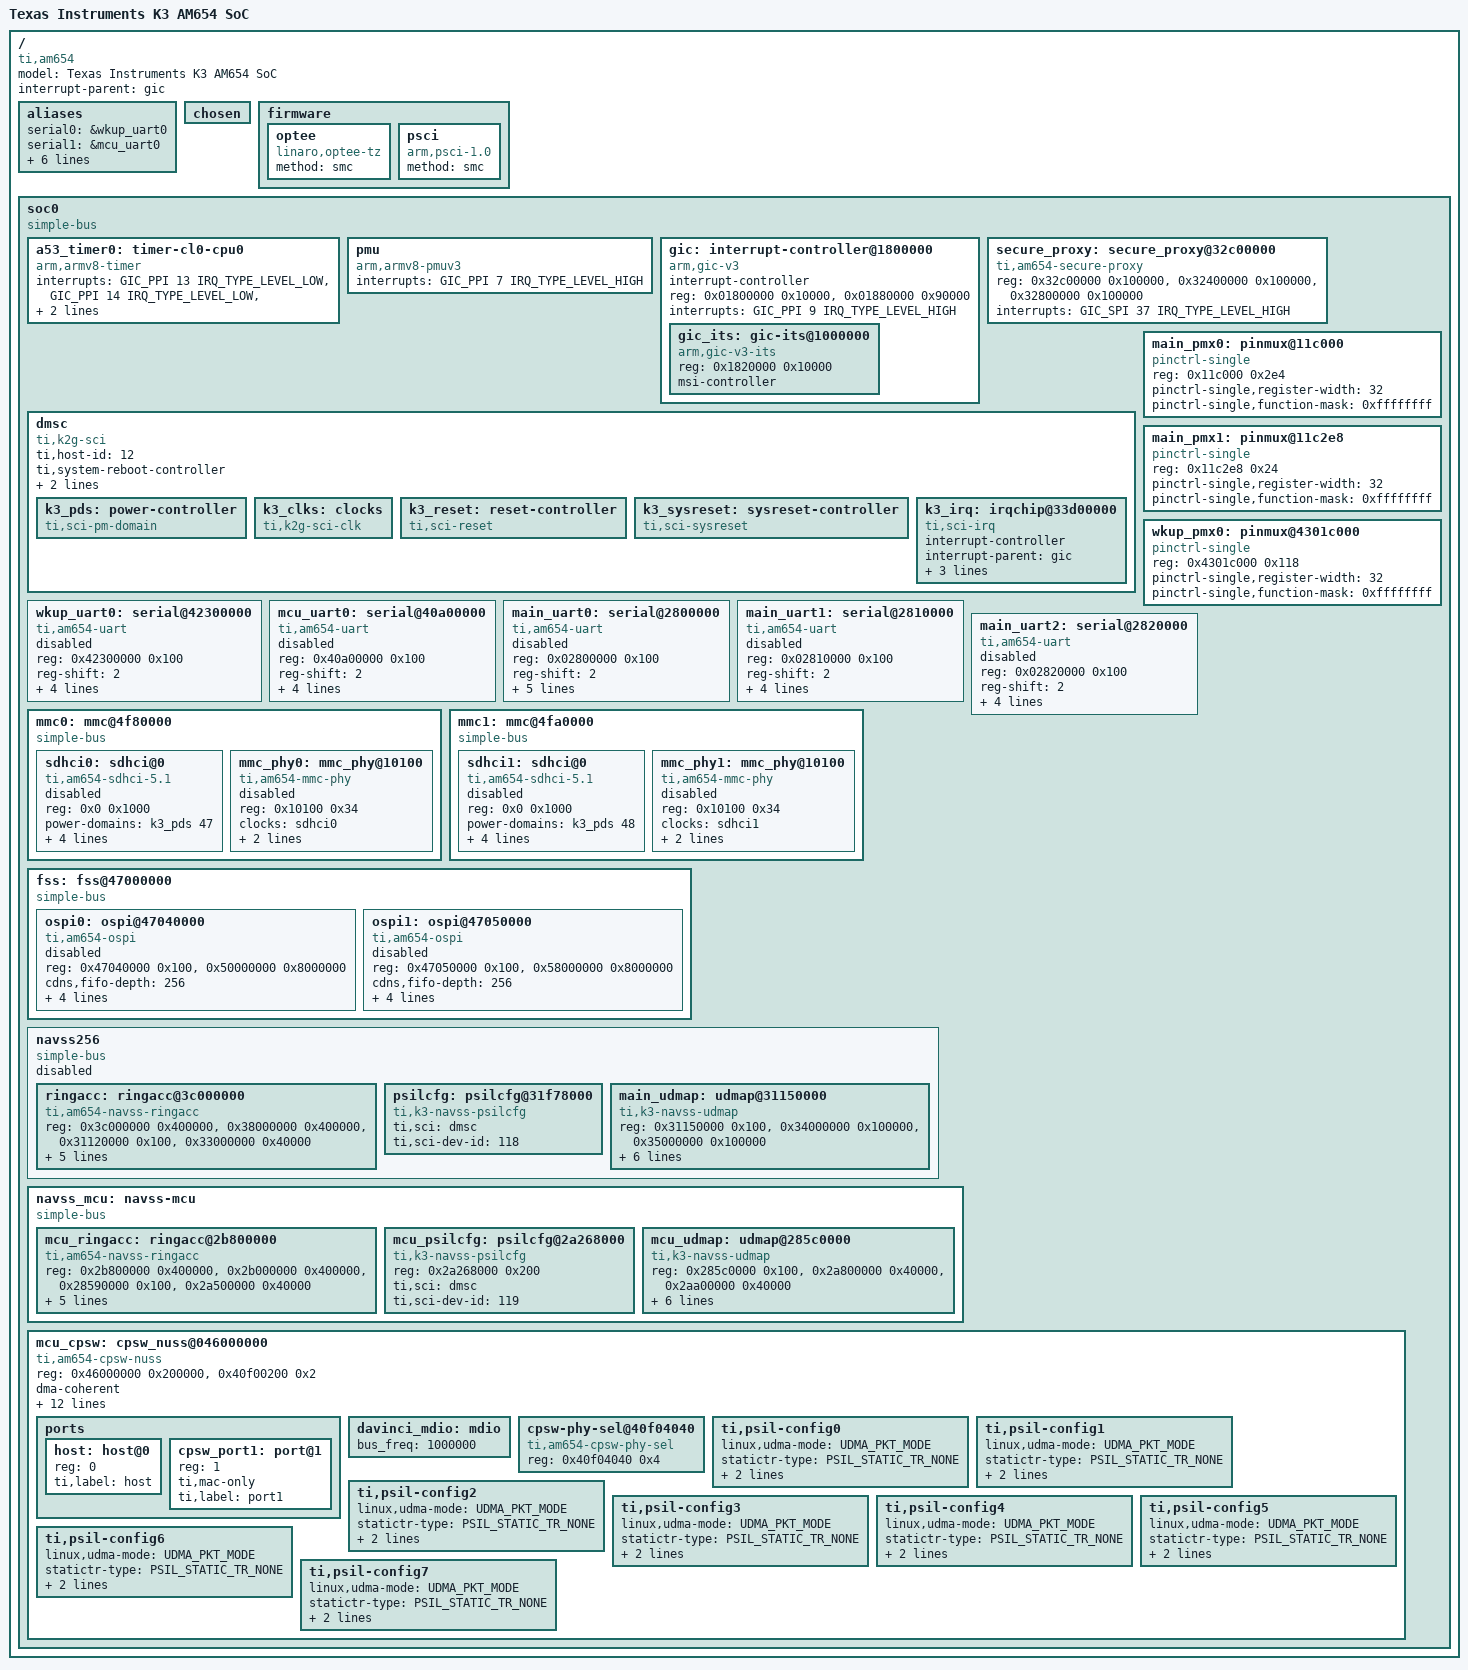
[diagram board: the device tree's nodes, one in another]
// SPDX-License-Identifier: GPL-2.0
/*
 * Device Tree Source for AM6 SoC Family
 *
 * Copyright (C) 2016-2018 Texas Instruments Incorporated - http://www.ti.com/
 */

#include <dt-bindings/gpio/gpio.h>
#include <dt-bindings/interrupt-controller/irq.h>
#include <dt-bindings/interrupt-controller/arm-gic.h>
#include <dt-bindings/pinctrl/k3-am6.h>
#include <dt-bindings/dma/k3-udma.h>

/ {
	model = "Texas Instruments K3 AM654 SoC";
	compatible = "ti,am654";
	interrupt-parent = <&gic>;
	#address-cells = <1>;
	#size-cells = <1>;

	aliases {
		serial0 = &wkup_uart0;
		serial1 = &mcu_uart0;
		serial2 = &main_uart0;
		serial3 = &main_uart1;
		serial4 = &main_uart2;
		spi0 = &ospi0;
		spi1 = &ospi1;
		ethernet0 = &cpsw_port1;
	};

	chosen { };

	firmware {
		optee {
			compatible = "linaro,optee-tz";
			method = "smc";
		};

		psci: psci {
			compatible = "arm,psci-1.0";
			method = "smc";
		};
	};

	soc0: soc0 {
		compatible = "simple-bus";
		#address-cells = <1>;
		#size-cells = <1>;
		ranges;

		a53_timer0: timer-cl0-cpu0 {
			compatible = "arm,armv8-timer";
			interrupts = <GIC_PPI 13 IRQ_TYPE_LEVEL_LOW>, /* cntpsirq */
				     <GIC_PPI 14 IRQ_TYPE_LEVEL_LOW>, /* cntpnsirq */
				     <GIC_PPI 11 IRQ_TYPE_LEVEL_LOW>, /* cntvirq */
				     <GIC_PPI 10 IRQ_TYPE_LEVEL_LOW>; /* cnthpirq */
		};

		pmu: pmu {
			compatible = "arm,armv8-pmuv3";
			/* Recommendation from GIC500 TRM Table A.3 */
			interrupts = <GIC_PPI 7 IRQ_TYPE_LEVEL_HIGH>;
		};

		gic: interrupt-controller@1800000 {
			compatible = "arm,gic-v3";
			#address-cells = <1>;
			#size-cells = <1>;
			ranges;
			#interrupt-cells = <3>;
			interrupt-controller;
			/*
			 * NOTE: we are NOT gicv2 backward compat, so no GICC,
			 * GICH or GICV
			 */
			reg = <0x01800000 0x10000>,	/* GICD */
			      <0x01880000 0x90000>;	/* GICR */

			/*
			 * vcpumntirq:
			 * virtual CPU interface maintenance interrupt
			 */
			interrupts = <GIC_PPI 9 IRQ_TYPE_LEVEL_HIGH>;

			gic_its: gic-its@1000000 {
				compatible = "arm,gic-v3-its";
				reg = <0x1820000 0x10000>;
				msi-controller;
				#msi-cells = <1>;
			};
		};

		secure_proxy: secure_proxy@32c00000 {
			compatible = "ti,am654-secure-proxy";
			#mbox-cells = <1>;
			reg-names = "target_data", "rt", "scfg";
			reg = <0x32c00000 0x100000>,
			      <0x32400000 0x100000>,
			      <0x32800000 0x100000>;
			interrupt-names = "rx_011";
			interrupts = <GIC_SPI 37 IRQ_TYPE_LEVEL_HIGH>;
		};

		dmsc: dmsc {
			compatible = "ti,k2g-sci";
			ti,host-id = <12>;
			#address-cells = <1>;
			#size-cells = <1>;
			ranges;
			/*
			 * In case of rare platforms that does not use am6 as
			 * system master, use /delete-property/
			 */
			ti,system-reboot-controller;
			mbox-names = "rx", "tx";

			mboxes= <&secure_proxy 11>,
				<&secure_proxy 13>;

			k3_pds: power-controller {
				compatible = "ti,sci-pm-domain";
				#power-domain-cells = <1>;
			};

			k3_clks: clocks {
				compatible = "ti,k2g-sci-clk";
				#clock-cells = <2>;
			};

			k3_reset: reset-controller {
				compatible = "ti,sci-reset";
				#reset-cells = <2>;
			};

			k3_sysreset: sysreset-controller {
				compatible = "ti,sci-sysreset";
			};

			k3_irq: irqchip@33d00000 {
				compatible = "ti,sci-irq";
				interrupt-controller;
				interrupt-parent = <&gic>;
				#interrupt-cells = <3>;
				reg = <0x33d00000 0x100000>,
				      <0x33c00000 0x40000>,
				      <0x33c40000 0x40000>,
				      <0x2a700000 0x100000>;
				ia-ids = <179>, <180>, <181>, <189>;
			};
		};

		main_pmx0: pinmux@11c000 {
			compatible = "pinctrl-single";
			reg = <0x11c000 0x2e4>;
			#pinctrl-cells = <1>;
			pinctrl-single,register-width = <32>;
			pinctrl-single,function-mask = <0xffffffff>;
		};

		main_pmx1: pinmux@11c2e8 {
			compatible = "pinctrl-single";
			reg = <0x11c2e8 0x24>;
			#pinctrl-cells = <1>;
			pinctrl-single,register-width = <32>;
			pinctrl-single,function-mask = <0xffffffff>;
		};

		wkup_pmx0: pinmux@4301c000 {
			compatible = "pinctrl-single";
			reg = <0x4301c000 0x118>;
			#pinctrl-cells = <1>;
			pinctrl-single,register-width = <32>;
			pinctrl-single,function-mask = <0xffffffff>;
		};

		wkup_uart0: serial@42300000 {
			compatible = "ti,am654-uart", "ti,omap4-uart", "ns16550a";
			reg = <0x42300000 0x100>;
			reg-shift = <2>;
			reg-io-width = <4>;
			interrupts = <GIC_SPI 697 IRQ_TYPE_LEVEL_HIGH>;
			clock-frequency = <48000000>;
			current-speed = <115200>;
			status = "disabled";
		};

		mcu_uart0: serial@40a00000 {
			compatible = "ti,am654-uart", "ti,omap4-uart", "ns16550a";
			reg = <0x40a00000 0x100>;
			reg-shift = <2>;
			reg-io-width = <4>;
			interrupts = <GIC_SPI 565 IRQ_TYPE_LEVEL_HIGH>;
			clock-frequency = <96000000>;
			current-speed = <115200>;
			status = "disabled";
		};

		main_uart0: serial@2800000 {
			compatible = "ti,am654-uart", "ti,omap4-uart", "ns16550a";
			reg = <0x02800000 0x100>;
			reg-shift = <2>;
			reg-io-width = <4>;
			interrupts = <GIC_SPI 192 IRQ_TYPE_LEVEL_HIGH>;
			clock-frequency = <48000000>;
			current-speed = <115200>;
			status = "disabled";
			u-boot,dm-pre-reloc;
		};

		main_uart1: serial@2810000 {
			compatible = "ti,am654-uart", "ti,omap4-uart", "ns16550a";
			reg = <0x02810000 0x100>;
			reg-shift = <2>;
			reg-io-width = <4>;
			interrupts = <GIC_SPI 193 IRQ_TYPE_LEVEL_HIGH>;
			clock-frequency = <48000000>;
			current-speed = <115200>;
			status = "disabled";
		};

		main_uart2: serial@2820000 {
			compatible = "ti,am654-uart", "ti,omap4-uart", "ns16550a";
			reg = <0x02820000 0x100>;
			reg-shift = <2>;
			reg-io-width = <4>;
			interrupts = <GIC_SPI 194 IRQ_TYPE_LEVEL_HIGH>;
			clock-frequency = <48000000>;
			current-speed = <115200>;
			status = "disabled";
		};

		mmc0: mmc@4f80000 {
			compatible = "simple-bus";
			#address-cells = <1>;
			#size-cells = <1>;
			ranges = <0x0 0x4f80000 0x20000>;

			sdhci0: sdhci@0 {
				compatible = "ti,am654-sdhci-5.1", "arasan,sdhci-5.1";
				reg = <0x0 0x1000>;
				power-domains = <&k3_pds 47>;
				clocks = <&k3_clks 47 0>, <&k3_clks 47 1>;
				clock-names = "clk_ahb", "clk_xin";
				interrupts = <GIC_SPI 136 IRQ_TYPE_LEVEL_HIGH>;
				clock-output-names = "emmc_cardclck";
				#clock-cells = <0>;
				phys=<&mmc_phy0>;
				phy-names = "phy_arasan";
				status = "disabled";
			};

			mmc_phy0: mmc_phy@10100 {
				compatible = "ti,am654-mmc-phy";
				reg = <0x10100 0x34>;
				clocks = <&sdhci0>;
				clock-names = "mmcclk";
				#phy-cells = <0>;
				ti,otap-del-sel = <0x2>;
				ti,trm-icp = <0x8>;
				status = "disabled";
			};
		};

		mmc1: mmc@4fa0000 {
			compatible = "simple-bus";
			#address-cells = <1>;
			#size-cells = <1>;
			ranges = <0x0 0x4fa0000 0x20000>;

			sdhci1: sdhci@0 {
				compatible = "ti,am654-sdhci-5.1", "arasan,sdhci-5.1";
				reg = <0x0 0x1000>;
				power-domains = <&k3_pds 48>;
				clocks = <&k3_clks 48 0>, <&k3_clks 48 1>;
				clock-names = "clk_ahb", "clk_xin";
				interrupts = <GIC_SPI 137 IRQ_TYPE_LEVEL_HIGH>;
				clock-output-names = "mmc_cardclck";
				#clock-cells = <0>;
				phys=<&mmc_phy1>;
				phy-names = "phy_arasan";
				status = "disabled";
			};

			mmc_phy1: mmc_phy@10100 {
				compatible = "ti,am654-mmc-phy";
				reg = <0x10100 0x34>;
				clocks = <&sdhci1>;
				clock-names = "mmcclk";
				#phy-cells = <0>;
				ti,otap-del-sel = <0x2>;
				ti,trm-icp = <0x8>;
				status = "disabled";
			};
		};

		fss: fss@47000000 {
			compatible = "simple-bus";
			#address-cells = <1>;
			#size-cells = <1>;
			ranges;

			ospi0: ospi@47040000 {
				compatible = "ti,am654-ospi", "cdns,qspi-nor";
				reg = <0x47040000 0x100>,
					<0x50000000 0x8000000>;
				cdns,fifo-depth = <256>;
				cdns,fifo-width = <4>;
				cdns,trigger-address = <0x50000000>;
				clocks = <&k3_clks 55 5>;
				power-domains = <&k3_pds 55>;
				#address-cells = <1>;
				#size-cells = <0>;
				status = "disabled";
			};

			ospi1: ospi@47050000 {
				compatible = "ti,am654-ospi", "cdns,qspi-nor";
				reg = <0x47050000 0x100>,
					<0x58000000 0x8000000>;
				cdns,fifo-depth = <256>;
				cdns,fifo-width = <4>;
				cdns,trigger-address = <0x58000000>;
				clocks = <&k3_clks 55 16>;
				power-domains = <&k3_pds 55>;
				#address-cells = <1>;
				#size-cells = <0>;
				status = "disabled";
			};
		};

		navss256: navss256 {
			compatible = "simple-bus";
			#address-cells = <1>;
			#size-cells = <1>;
			status = "disabled";

			ringacc: ringacc@3c000000 {
				compatible = "ti,am654-navss-ringacc";
				reg = <0x3c000000 0x400000>,
					<0x38000000 0x400000>,
					<0x31120000 0x100>,
					<0x33000000 0x40000>;
				reg-names = "rt", "fifos",
					    "proxy_gcfg", "proxy_target";
				ti,num-rings = <818>;
				ti,gp-rings = <302 466>; /* start, cnt */
				ti,dma-ring-reset-quirk;
				ti,sci = <&dmsc>;
				ti,sci-dev-id = <187>;
			};

			psilcfg: psilcfg@31f78000 {
				compatible = "ti,k3-navss-psilcfg";

				ti,sci = <&dmsc>;
				ti,sci-dev-id = <118>;
			};

			main_udmap: udmap@31150000 {
				compatible = "ti,k3-navss-udmap";
				reg =	<0x31150000 0x100>,
					<0x34000000 0x100000>,
					<0x35000000 0x100000>;
				reg-names = "gcfg", "rchanrt", "tchanrt";
				#dma-cells = <3>;
				dma-channels = <270>;

				ti,psi-proxy = <&psilcfg>;
				ti,ringacc = <&ringacc>;
				ti,psil-base = <0x1000>;

				ti,sci = <&dmsc>;
				ti,sci-dev-id = <188>;
			};
		};

		navss_mcu: navss-mcu {
			compatible = "simple-bus";
			#address-cells = <1>;
			#size-cells = <1>;

			mcu_ringacc: ringacc@2b800000 {
				compatible = "ti,am654-navss-ringacc";
				reg = <0x2b800000 0x400000>,
					<0x2b000000 0x400000>,
					<0x28590000 0x100>,
					<0x2a500000 0x40000>;
				reg-names = "rt", "fifos",
					"proxy_gcfg", "proxy_target";
				ti,num-rings = <286>;
				ti,gp-rings = <96 255>; /* start, cnt */
				ti,dma-ring-reset-quirk;
				ti,sci = <&dmsc>;
				ti,sci-dev-id = <195>;
			};

			mcu_psilcfg: psilcfg@2a268000 {
				compatible = "ti,k3-navss-psilcfg";
				reg = <0x2a268000 0x200>;
				ti,sci = <&dmsc>;
				ti,sci-dev-id = <119>;
			};

			mcu_udmap: udmap@285c0000 {
				compatible = "ti,k3-navss-udmap";
				reg =	<0x285c0000 0x100>,
					<0x2a800000 0x40000>,
					<0x2aa00000 0x40000>;
				reg-names = "gcfg", "rchanrt", "tchanrt";
				#dma-cells = <3>;
				dma-channels = <96>;

				ti,psi-proxy = <&mcu_psilcfg>;
				ti,ringacc = <&mcu_ringacc>;
				ti,psil-base = <0x6000>;
				ti,sci = <&dmsc>;
				ti,sci-dev-id = <194>;
			};
		};

		mcu_cpsw: cpsw_nuss@046000000 {
			compatible = "ti,am654-cpsw-nuss";
			#address-cells = <1>;
			#size-cells = <1>;
			reg = <0x46000000 0x200000>, <0x40f00200 0x2>;
			reg-names = "cpsw_nuss", "mac_efuse";
			ranges;
			dma-coherent;
			clocks = <&k3_clks 5 10>;
			clock-names = "fck";
			power-domains = <&k3_pds 5>;
			ti,psil-base = <0x7000>;

			dmas = <&mcu_udmap &mcu_cpsw 0 UDMA_DIR_TX>,
			       <&mcu_udmap &mcu_cpsw 1 UDMA_DIR_TX>,
			       <&mcu_udmap &mcu_cpsw 2 UDMA_DIR_TX>,
			       <&mcu_udmap &mcu_cpsw 3 UDMA_DIR_TX>,
			       <&mcu_udmap &mcu_cpsw 4 UDMA_DIR_TX>,
			       <&mcu_udmap &mcu_cpsw 5 UDMA_DIR_TX>,
			       <&mcu_udmap &mcu_cpsw 6 UDMA_DIR_TX>,
			       <&mcu_udmap &mcu_cpsw 7 UDMA_DIR_TX>,
			       <&mcu_udmap &mcu_cpsw 0 UDMA_DIR_RX>;
			dma-names = "tx0", "tx1", "tx2", "tx3",
				    "tx4", "tx5", "tx6", "tx7",
				    "rx";

			ports {
				#address-cells = <1>;
				#size-cells = <0>;

				host: host@0 {
					reg = <0>;
					ti,label = "host";
				};

				cpsw_port1: port@1 {
					reg = <1>;
					ti,mac-only;
					ti,label = "port1";
				};
			};

			davinci_mdio: mdio {
				#address-cells = <1>;
				#size-cells = <0>;
				bus_freq = <1000000>;
			};

			cpsw-phy-sel@40f04040 {
				compatible = "ti,am654-cpsw-phy-sel";
				reg= <0x40f04040 0x4>;
				reg-names = "gmii-sel";
			};

			ti,psil-config0 {
				linux,udma-mode = <UDMA_PKT_MODE>;
				statictr-type = <PSIL_STATIC_TR_NONE>;
				ti,needs-epib;
				ti,psd-size = <16>;
			};

			ti,psil-config1 {
				linux,udma-mode = <UDMA_PKT_MODE>;
				statictr-type = <PSIL_STATIC_TR_NONE>;
				ti,needs-epib;
				ti,psd-size = <16>;
			};

			ti,psil-config2 {
				linux,udma-mode = <UDMA_PKT_MODE>;
				statictr-type = <PSIL_STATIC_TR_NONE>;
				ti,needs-epib;
				ti,psd-size = <16>;
			};

			ti,psil-config3 {
				linux,udma-mode = <UDMA_PKT_MODE>;
				statictr-type = <PSIL_STATIC_TR_NONE>;
				ti,needs-epib;
				ti,psd-size = <16>;
			};

			ti,psil-config4 {
				linux,udma-mode = <UDMA_PKT_MODE>;
				statictr-type = <PSIL_STATIC_TR_NONE>;
				ti,needs-epib;
				ti,psd-size = <16>;
			};

			ti,psil-config5 {
				linux,udma-mode = <UDMA_PKT_MODE>;
				statictr-type = <PSIL_STATIC_TR_NONE>;
				ti,needs-epib;
				ti,psd-size = <16>;
			};

			ti,psil-config6 {
				linux,udma-mode = <UDMA_PKT_MODE>;
				statictr-type = <PSIL_STATIC_TR_NONE>;
				ti,needs-epib;
				ti,psd-size = <16>;
			};

			ti,psil-config7 {
				linux,udma-mode = <UDMA_PKT_MODE>;
				statictr-type = <PSIL_STATIC_TR_NONE>;
				ti,needs-epib;
				ti,psd-size = <16>;
			};
		};
	};
};
